# MKL28T7_CORE1 register map
Vendor: Freescale Semiconductor, Inc.; Series: Kinetis_L; File version: 1.6
CPU: CM0PLUS r0p0, little endian, no MPU, no FPU, VTOR, 2 interrupt priority bits
Registers are 32-bit, read-write, reset 0x0 unless marked. A register's access mark holds for its fields unless they carry their own. Offsets are from the block's base; [hi:lo] are bit positions; {n}, {i} and the like mark numbered series.

## DAC0 — 12-Bit Digital-to-Analog Converter
Base 0x4006A000; register names take the prefix DAC0_
{0x0+2i} DAT{i}L (i=0..15) 8-bit — DAC Data Low Register
  [7:0] DATA0
{0x1+2i} DAT{i}H (i=0..15) 8-bit — DAC Data High Register
  [3:0] DATA1
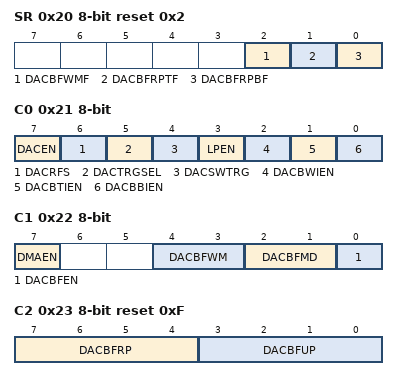
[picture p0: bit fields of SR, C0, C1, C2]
0x20 SR 8-bit reset 0x2 — DAC Status Register
  [2] DACBFWMF — DAC Buffer Watermark Flag
    0=The DAC buffer read pointer has not reached the watermark level; 1=The DAC buffer read pointer has reached the watermark level
  [1] DACBFRPTF — DAC Buffer Read Pointer Top Position Flag
    0=The DAC buffer read pointer is not zero; 1=The DAC buffer read pointer is zero
  [0] DACBFRPBF — DAC Buffer Read Pointer Bottom Position Flag
    0=The DAC buffer read pointer is not equal to C2[DACBFUP]; 1=The DAC buffer read pointer is equal to C2[DACBFUP]
0x21 C0 8-bit — DAC Control Register
  [7] DACEN — DAC Enable
    0=The DAC system is disabled; 1=The DAC system is enabled
  [6] DACRFS — DAC Reference Select
    0=The DAC selects DACREF_1 as the reference voltage; 1=The DAC selects DACREF_2 as the reference voltage
  [5] DACTRGSEL — DAC Trigger Select
    0=The DAC hardware trigger is selected; 1=The DAC software trigger is selected
  [4] DACSWTRG wo — DAC Software Trigger
    0=The DAC soft trigger is not valid; 1=The DAC soft trigger is valid
  [3] LPEN — DAC Low Power Control
    0=High-Power mode; 1=Low-Power mode
  [2] DACBWIEN — DAC Buffer Watermark Interrupt Enable
    0=The DAC buffer watermark interrupt is disabled; 1=The DAC buffer watermark interrupt is enabled
  [1] DACBTIEN — DAC Buffer Read Pointer Top Flag Interrupt Enable
    0=The DAC buffer read pointer top flag interrupt is disabled; 1=The DAC buffer read pointer top flag interrupt is enabled
  [0] DACBBIEN — DAC Buffer Read Pointer Bottom Flag Interrupt Enable
    0=The DAC buffer read pointer bottom flag interrupt is disabled; 1=The DAC buffer read pointer bottom flag interrupt is enabled
0x22 C1 8-bit — DAC Control Register 1
  [7] DMAEN — DMA Enable Select
    0=DMA is disabled; 1=DMA is enabled. When DMA is enabled, the DMA request will be generated by original interrupts. The interrupts will not be presented on this module at the same time.
  [4:3] DACBFWM — DAC Buffer Watermark Select
    0=In normal mode, 1 word . In FIFO mode, 2 or less than 2 data remaining in FIFO will set watermark status bit.; 1=In normal mode, 2 words . In FIFO mode, Max/4 or less than Max/4 data remaining in FIFO will set watermark status bit.; 2=In normal mode, 3 words . In FIFO mode, Max/2 or less than Max/2 data remaining in FIFO will set watermark status bit.; 3=In normal mode, 4 words . In FIFO mode, Max-2 or less than Max-2 data remaining in FIFO will set watermark status bit.
  [2:1] DACBFMD — DAC Buffer Work Mode Select
    0=Normal mode; 1=Swing mode; 2=One-Time Scan mode; 3=FIFO mode
  [0] DACBFEN — DAC Buffer Enable
    0=Buffer read pointer is disabled. The converted data is always the first word of the buffer.; 1=Buffer read pointer is enabled. The converted data is the word that the read pointer points to. It means converted data can be from any word of the buffer.
0x23 C2 8-bit reset 0xF — DAC Control Register 2
  [7:4] DACBFRP — DAC Buffer Read Pointer
  [3:0] DACBFUP — DAC Buffer Upper Limit

## CMP0 — High-Speed Comparator (CMP), Voltage Reference (VREF) Digital-to-Analog Converter (DAC), and Analog Mux (ANMUX)
Base 0x4006E000; register names take the prefix CMP0_
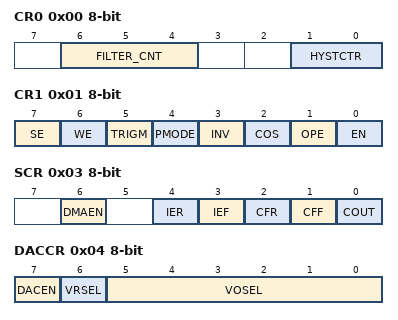
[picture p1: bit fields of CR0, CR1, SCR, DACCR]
0x00 CR0 8-bit — CMP Control Register 0
  [6:4] FILTER_CNT — Filter Sample Count
    0=Filter is disabled. If SE = 1, then COUT is a logic 0. This is not a legal state, and is not recommended. If SE = 0, COUT = COUTA.; 1=One sample must agree. The comparator output is simply sampled.; {v}={v} consecutive samples must agree (v=2..7)
  [1:0] HYSTCTR — Comparator hard block hysteresis control
    {v}=Level {v} (v=0..3)
0x01 CR1 8-bit — CMP Control Register 1
  [7] SE — Sample Enable
    0=Sampling mode is not selected; 1=Sampling mode is selected
  [6] WE — Windowing Enable
    0=Windowing mode is not selected; 1=Windowing mode is selected
  [5] TRIGM — Trigger Mode Enable
    0=Trigger mode is disabled; 1=Trigger mode is enabled
  [4] PMODE — Power Mode Select
    0=Low-Speed (LS) Comparison mode selected. In this mode, CMP has slower output propagation delay and lower current consumption.; 1=High-Speed (HS) Comparison mode selected. In this mode, CMP has faster output propagation delay and higher current consumption.
  [3] INV — Comparator INVERT
    0=Does not invert the comparator output; 1=Inverts the comparator output
  [2] COS — Comparator Output Select
    0=Set the filtered comparator output (CMPO) to equal COUT; 1=Set the unfiltered comparator output (CMPO) to equal COUTA
  [1] OPE — Comparator Output Pin Enable
    0=CMPO is not available on the associated CMPO output pin. If the comparator does not own the pin, this field has no effect.; 1=CMPO is available on the associated CMPO output pin. The comparator output (CMPO) is driven out on the associated CMPO output pin if the comparator owns the pin. If the comparator does not own the field, this bit has no effect.
  [0] EN — Comparator Module Enable
    0=Analog Comparator is disabled; 1=Analog Comparator is enabled
0x02 FPR 8-bit — CMP Filter Period Register
  [7:0] FILT_PER — Filter Sample Period
0x03 SCR 8-bit — CMP Status and Control Register
  [6] DMAEN — DMA Enable Control
    0=DMA is disabled; 1=DMA is enabled
  [4] IER — Comparator Interrupt Enable Rising
    0=Interrupt is disabled; 1=Interrupt is enabled
  [3] IEF — Comparator Interrupt Enable Falling
    0=Interrupt is disabled; 1=Interrupt is enabled
  [2] CFR — Analog Comparator Flag Rising
    0=Rising-edge on COUT has not been detected; 1=Rising-edge on COUT has occurred
  [1] CFF — Analog Comparator Flag Falling
    0=Falling-edge on COUT has not been detected; 1=Falling-edge on COUT has occurred
  [0] COUT ro — Analog Comparator Output
0x04 DACCR 8-bit — DAC Control Register
  [7] DACEN — DAC Enable
    0=DAC is disabled; 1=DAC is enabled
  [6] VRSEL — Supply Voltage Reference Source Select
    0=Vin1 is selected as resistor ladder network supply reference; 1=Vin2 is selected as resistor ladder network supply reference
  [5:0] VOSEL — DAC Output Voltage Select
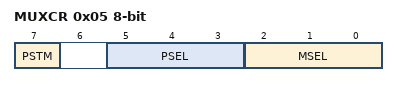
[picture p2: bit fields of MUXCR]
0x05 MUXCR 8-bit — MUX Control Register
  [7] PSTM — Pass Through Mode Enable
    0=Pass Through Mode is disabled; 1=Pass Through Mode is enabled
  [5:3] PSEL — Plus Input Mux Control
    {v}=IN{v} (v=0..7)
  [2:0] MSEL — Minus Input Mux Control
    {v}=IN{v} (v=0..7)

## CMP1 — High-Speed Comparator (CMP), Voltage Reference (VREF) Digital-to-Analog Converter (DAC), and Analog Mux (ANMUX)
Base 0x400EF000; register names take the prefix CMP1_
Registers as CMP0.
